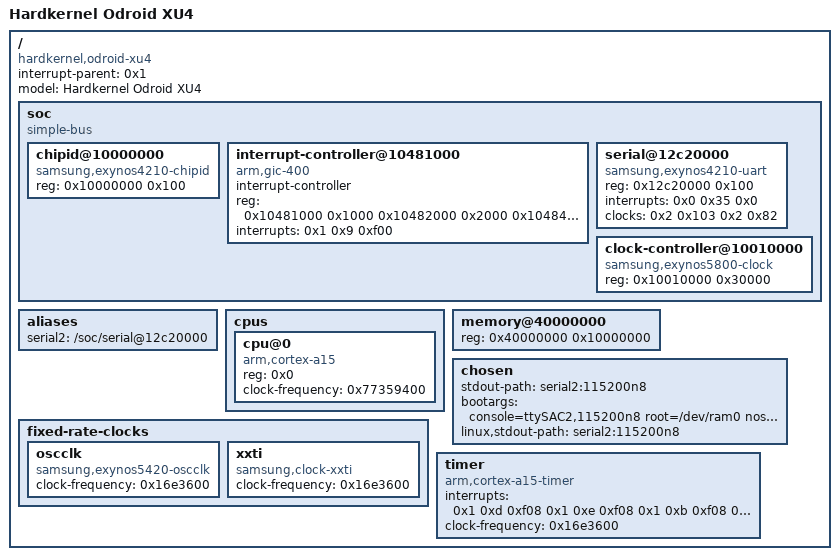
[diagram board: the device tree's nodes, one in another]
// Copyright Linux
// SPDX-License-Identifier: GPL-2.0-or-later

/dts-v1/;

/ {
	interrupt-parent = <0x1>;
	#address-cells = <0x1>;
	#size-cells = <0x1>;
	compatible = "hardkernel,odroid-xu4", "samsung,exynos5800", "samsung,exynos5";
	model = "Hardkernel Odroid XU4";

	soc {
        compatible = "simple-bus";
		#address-cells = <0x1>;
		#size-cells = <0x1>;
		ranges;

        chipid@10000000 {
			compatible = "samsung,exynos4210-chipid";
			reg = <0x10000000 0x100>;
		};

        interrupt-controller@10481000 {
			compatible = "arm,gic-400", "arm,cortex-a15-gic", "arm,cortex-a9-gic";
			#interrupt-cells = <0x3>;
			interrupt-controller;
			reg = <0x10481000 0x1000 0x10482000 0x2000 0x10484000 0x2000 0x10486000 0x2000>;
			interrupts = <0x1 0x9 0xf00>;
			linux,phandle = <0x1>;
			phandle = <0x1>;
		};

        serial@12c20000 {
			compatible = "samsung,exynos4210-uart";
			reg = <0x12c20000 0x100>;
			interrupts = <0x0 0x35 0x0>;
			clocks = <0x2 0x103 0x2 0x82>;
			clock-names = "uart", "clk_uart_baud0";
		};

        clock-controller@10010000 {
			compatible = "samsung,exynos5800-clock";
			reg = <0x10010000 0x30000>;
			#clock-cells = <0x1>;
			linux,phandle = <0x2>;
			phandle = <0x2>;
		};
    };

	aliases {
		serial2 = "/soc/serial@12c20000";
	};

    cpus {
		#address-cells = <0x1>;
		#size-cells = <0x0>;

		cpu@0 {
			device_type = "cpu";
			compatible = "arm,cortex-a15";
            reg = <0x0>;
			clock-frequency = <0x77359400>;
			linux,phandle = <0x18>;
			phandle = <0x18>;
        };
	};

	memory@40000000 {
		device_type = "memory";
		reg = <0x40000000 0x10000000>;
	};

	chosen {
		stdout-path = "serial2:115200n8";
		bootargs = "console=ttySAC2,115200n8 root=/dev/ram0 nosmp rw debug loglevel=8 earlyprintk=serial pci=nomsi";
		linux,stdout-path = "serial2:115200n8";
    };

	fixed-rate-clocks {
		oscclk {
			compatible = "samsung,exynos5420-oscclk";
			clock-frequency = <0x16e3600>;
		};
		xxti {
			compatible = "samsung,clock-xxti";
			clock-frequency = <0x16e3600>;
		};
	};

	timer {
		compatible = "arm,cortex-a15-timer", "arm,armv7-timer";
		interrupts = <0x1 0xd 0xf08 0x1 0xe 0xf08 0x1 0xb 0xf08 0x1 0xa 0xf08>;
		clock-frequency = <0x16e3600>;
	};

};
